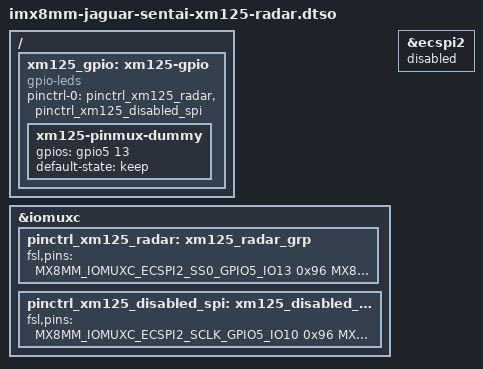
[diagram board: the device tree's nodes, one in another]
// SPDX-License-Identifier: (GPL-2.0 OR MIT)
/*
 * Device Tree Overlay for Acconeer XM125 Radar Module
 * Copyright 2025 Dynamic Devices Ltd
 * 
 * This overlay replaces the BGT 60TR13C radar with the Acconeer XM125
 * on the i.MX8MM Jaguar Sentai board.
 * 
 * Hardware Configuration:
 * - XM125 uses I2C3 for communication (default address 0x52)
 * - GPIO5_IO13 (ECSPI2_SS0) repurposed as bootloader control (BOOT0)
 * - GPIO4_IO28 (SAI3_RXFS) repurposed as reset control (active-low, shared with BGT radar)
 * - GPIO5_IO11 (ECSPI2_MOSI) repurposed as wake up control (assert high to wake up)
 * - GPIO4_IO29 (SAI3_RXC) repurposed as MCU interrupt input
 * - GPIO5_IO10 (ECSPI2_SCLK) disabled - goes to test point only
 * - GPIO5_IO12 (ECSPI2_MISO) disabled - goes to test point only
 * - ECSPI2 interface disabled (was used by BGT radar)
 * 
 * Usage:
 * - Applied automatically when MACHINE_FEATURES contains "xm125-radar"
 * - GPIO control via libgpiod from userspace
 * - I2C communication via /dev/i2c-2 (I2C3)
 */

/dts-v1/;
/plugin/;

#include <dt-bindings/gpio/gpio.h>
#include "freescale/imx8mm-pinfunc.h"

&iomuxc {
	/* XM125 radar GPIO pin configuration - repurpose ECSPI2 and SAI3 pins */
	pinctrl_xm125_radar: xm125_radar_grp {
		fsl,pins = <
			/* Bootloader control (BOOT0) - repurpose ECSPI2_SS0 as GPIO */
			MX8MM_IOMUXC_ECSPI2_SS0_GPIO5_IO13	0x96
			/* Reset control (active-low) - same pin as BGT radar reset */
			MX8MM_IOMUXC_SAI3_RXFS_GPIO4_IO28	0x96
			/* Wake up control (assert high to wake up) - repurpose ECSPI2_MOSI */
			MX8MM_IOMUXC_ECSPI2_MOSI_GPIO5_IO11	0x96
			/* MCU interrupt input - repurpose SAI3_RXC */
			MX8MM_IOMUXC_SAI3_RXC_GPIO4_IO29	0x96
		>;
	};
	
	/* Disable unused SPI pins - hardware team feedback: 
	 * SCLK and MISO just go to test points on radar board, not used by XM125 */
	pinctrl_xm125_disabled_spi: xm125_disabled_spi_grp {
		fsl,pins = <
			/* Disable ECSPI2_SCLK - not used by XM125, goes to test point */
			MX8MM_IOMUXC_ECSPI2_SCLK_GPIO5_IO10	0x96
			/* Disable ECSPI2_MISO - not used by XM125, goes to test point */
			MX8MM_IOMUXC_ECSPI2_MISO_GPIO5_IO12	0x96
		>;
	};
};

/* Disable BGT radar SPI interface */
&ecspi2 {
	status = "disabled";
};

/ {
	/* XM125 GPIO device node to ensure pinmux is applied */
	xm125_gpio: xm125-gpio {
		compatible = "gpio-leds"; /* Use gpio-leds as a simple way to apply pinctrl */
		pinctrl-names = "default";
		pinctrl-0 = <&pinctrl_xm125_radar>, <&pinctrl_xm125_disabled_spi>;
		status = "okay";
		
		/* Dummy LED entry to make gpio-leds happy - won't actually control LEDs */
		xm125-pinmux-dummy {
			gpios = <&gpio5 13 0>; /* Just reference one GPIO to satisfy driver */
			default-state = "keep"; /* Don't change the state */
		};
	};
};
